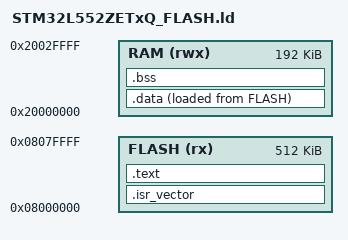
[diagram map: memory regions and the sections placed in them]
/* Linker script for STM32L552ZETxQ
 * Flash: 512 KB at 0x08000000
 * SRAM1: 192 KB at 0x20000000
 * SRAM2:  64 KB at 0x20030000
 */

ENTRY(Reset_Handler)

_estack = ORIGIN(RAM) + LENGTH(RAM);

MEMORY
{
    FLASH (rx)  : ORIGIN = 0x08000000, LENGTH = 512K
    RAM   (rwx) : ORIGIN = 0x20000000, LENGTH = 192K
}

SECTIONS
{
    .isr_vector :
    {
        . = ALIGN(4);
        KEEP(*(.vectors))
        . = ALIGN(4);
    } > FLASH

    .text :
    {
        . = ALIGN(4);
        *(.text)
        *(.text*)
        *(.rodata)
        *(.rodata*)
        . = ALIGN(4);
        _etext = .;
    } > FLASH

    _sidata = LOADADDR(.data);

    .data :
    {
        . = ALIGN(4);
        _sdata = .;
        *(.data)
        *(.data*)
        . = ALIGN(4);
        _edata = .;
    } > RAM AT> FLASH

    .bss :
    {
        . = ALIGN(4);
        _sbss = .;
        *(.bss)
        *(.bss*)
        *(COMMON)
        . = ALIGN(4);
        _ebss = .;
    } > RAM

    /DISCARD/ :
    {
        libc.a (*)
        libm.a (*)
        libgcc.a (*)
    }
}
